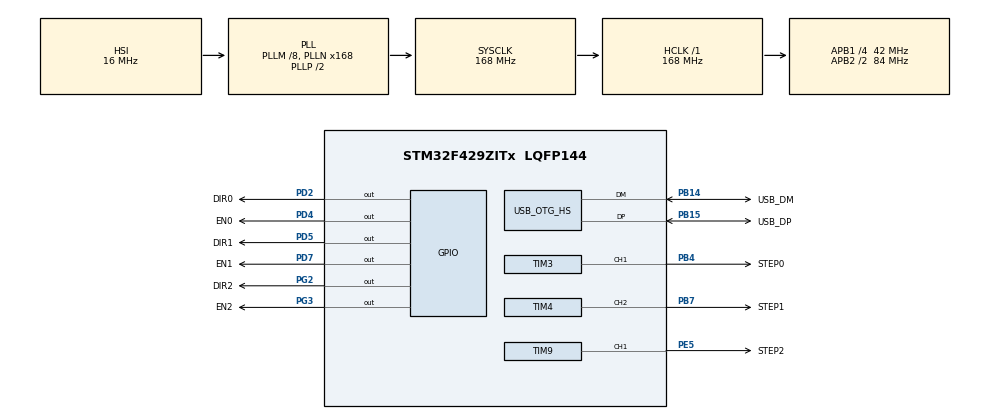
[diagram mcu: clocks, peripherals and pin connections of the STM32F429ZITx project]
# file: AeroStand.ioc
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Mcu.Family=STM32F4
Mcu.Name=STM32F429ZITx
Mcu.Package=LQFP144
NVIC.OTG_HS_IRQn=true\:0\:0\:false\:false\:true\:false\:true\:true
NVIC.TIM1_BRK_TIM9_IRQn=true\:1\:0\:false\:false\:true\:false\:true\:true
NVIC.TIM3_IRQn=true\:1\:0\:false\:false\:true\:false\:true\:true
NVIC.TIM4_IRQn=true\:1\:0\:false\:false\:true\:false\:true\:true
NVIC.PriorityGroup=NVIC_PRIORITYGROUP_4
PA13.GPIO_Label=TMS
PA13.Mode=Serial_Wire
PA13.Signal=SYS_JTMS-SWDIO
PA14.GPIO_Label=TCK
PA14.Mode=Serial_Wire
PA14.Signal=SYS_JTCK-SWCLK
PB14.GPIO_Label=USB_DM
PB14.Mode=Device_Only_FS
PB14.Signal=USB_OTG_HS_DM
PB15.GPIO_Label=USB_DP
PB15.Mode=Device_Only_FS
PB15.Signal=USB_OTG_HS_DP
PB4.GPIO_Label=STEP0
PB4.Signal=S_TIM3_CH1
PB7.GPIO_Label=STEP1
PB7.Signal=S_TIM4_CH2
PD2.GPIO_Label=DIR0
PD2.PinState=GPIO_PIN_RESET
PD2.Signal=GPIO_Output
PD4.GPIO_Label=EN0
PD4.PinState=GPIO_PIN_SET
PD4.Signal=GPIO_Output
PD5.GPIO_Label=DIR1
PD5.PinState=GPIO_PIN_RESET
PD5.Signal=GPIO_Output
PD7.GPIO_Label=EN1
PD7.PinState=GPIO_PIN_SET
PD7.Signal=GPIO_Output
PE5.GPIO_Label=STEP2
PE5.Signal=S_TIM9_CH1
PG2.GPIO_Label=DIR2
PG2.PinState=GPIO_PIN_RESET
PG2.Signal=GPIO_Output
PG3.GPIO_Label=EN2
PG3.PinState=GPIO_PIN_SET
PG3.Signal=GPIO_Output
ProjectManager.HeapSize=0x200
ProjectManager.StackSize=0x400
ProjectManager.TargetToolchain=STM32CubeIDE
RCC.48MHZClocksFreq_Value=48000000
RCC.AHBFreq_Value=168000000
RCC.APB1CLKDivider=RCC_HCLK_DIV4
RCC.APB1Freq_Value=42000000
RCC.APB1TimFreq_Value=84000000
RCC.APB2CLKDivider=RCC_HCLK_DIV2
RCC.APB2Freq_Value=84000000
RCC.APB2TimFreq_Value=168000000
RCC.CortexFreq_Value=168000000
RCC.HCLKFreq_Value=168000000
RCC.HSE_VALUE=8000000
RCC.HSI_VALUE=16000000
RCC.LSE_VALUE=32768
RCC.PLLM=8
RCC.PLLN=168
RCC.PLLSourceVirtual=RCC_PLLSOURCE_HSI
RCC.PLLP=RCC_PLLP_DIV2
RCC.PLLQ=7
RCC.SYSCLKFreq_VALUE=168000000
RCC.SYSCLKSource=RCC_SYSCLKSOURCE_PLLCLK
RCC.VCOOutputFreq_Value=336000000
SH.S_TIM3_CH1.0=TIM3_CH1,PWM Generation1 CH1
SH.S_TIM4_CH2.0=TIM4_CH2,PWM Generation2 CH2
SH.S_TIM9_CH1.0=TIM9_CH1,PWM Generation1 CH1
TIM3.Channel-PWM\ Generation1\ CH1=TIM_CHANNEL_1
TIM4.Channel-PWM\ Generation2\ CH2=TIM_CHANNEL_2
TIM9.Channel-PWM\ Generation1\ CH1=TIM_CHANNEL_1
USB_DEVICE.CLASS_NAME_HS=CDC
USB_DEVICE.VirtualMode-CDC_HS=Cdc
USB_DEVICE.VirtualModeHS=Cdc_HS
USB_OTG_HS.VirtualMode-Device_Only_FS=Device_Only_FS
VP_TIM3_VS_ClockSourceINT.Mode=Internal
VP_TIM4_VS_ClockSourceINT.Mode=Internal
VP_TIM9_VS_ClockSourceINT.Mode=Internal
VP_USB_DEVICE_VS_USB_DEVICE_CDC_HS.Mode=CDC_HS
board=STM32F429I-DISC1

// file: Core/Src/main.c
/* USER CODE BEGIN Header */
/**
  ******************************************************************************
  * @file           : main.c
  * @brief          : Main program body
  ******************************************************************************
  * @attention
  *
  * Copyright (c) 2026 STMicroelectronics.
  * All rights reserved.
  *
  * This software is licensed under terms that can be found in the LICENSE file
  * in the root directory of this software component.
  * If no LICENSE file comes with this software, it is provided AS-IS.
  *
  ******************************************************************************
  */
/* USER CODE END Header */
#include "main.h"
#include "usb_device.h"

/* USER CODE BEGIN Includes */
#include "stepper.h"
#include "cmd_parser.h"
#include "lcd_status.h"
#include "scenario.h"

/* USER CODE END Includes */

TIM_HandleTypeDef htim3;
TIM_HandleTypeDef htim4;
TIM_HandleTypeDef htim9;

void SystemClock_Config(void);
static void MX_GPIO_Init(void);
static void MX_TIM3_Init(void);
static void MX_TIM4_Init(void);
static void MX_TIM9_Init(void);

int main(void)
{

  /* MCU Configuration--------------------------------------------------------*/

  /* Reset of all peripherals, Initializes the Flash interface and the Systick. */
  HAL_Init();

  /* Configure the system clock */
  SystemClock_Config();

  /* Initialize all configured peripherals */
  MX_GPIO_Init();
  MX_TIM3_Init();
  MX_TIM4_Init();
  MX_TIM9_Init();
  MX_USB_DEVICE_Init();
  /* USER CODE BEGIN 2 */
  stepper_init();
  cmd_init();
  (void)lcd_status_init();

  /* USER CODE END 2 */

  /* Infinite loop */
  while (1)
  {

    /* USER CODE BEGIN 3 */
    cmd_poll();
    scenario_update();
    lcd_status_update();
  }
  /* USER CODE END 3 */
}

void SystemClock_Config(void)
{
  RCC_OscInitTypeDef RCC_OscInitStruct = {0};
  RCC_ClkInitTypeDef RCC_ClkInitStruct = {0};

  /** Configure the main internal regulator output voltage
  */
  __HAL_RCC_PWR_CLK_ENABLE();
  __HAL_PWR_VOLTAGESCALING_CONFIG(PWR_REGULATOR_VOLTAGE_SCALE1);

  /** HSI 16 МГц -> PLL: VCO 16/8 = 2 МГц x 168 = 336, SYSCLK 168, USB 48 (HSE на плате не стартует) */
  RCC_OscInitStruct.OscillatorType = RCC_OSCILLATORTYPE_HSI;
  RCC_OscInitStruct.HSIState = RCC_HSI_ON;
  RCC_OscInitStruct.HSICalibrationValue = RCC_HSICALIBRATION_DEFAULT;
  RCC_OscInitStruct.PLL.PLLState = RCC_PLL_ON;
  RCC_OscInitStruct.PLL.PLLSource = RCC_PLLSOURCE_HSI;
  RCC_OscInitStruct.PLL.PLLM = 8;
  RCC_OscInitStruct.PLL.PLLN = 168;
  RCC_OscInitStruct.PLL.PLLP = RCC_PLLP_DIV2;
  RCC_OscInitStruct.PLL.PLLQ = 7;
  if (HAL_RCC_OscConfig(&RCC_OscInitStruct) != HAL_OK)
  {
    Error_Handler();
  }

  /** Initializes the CPU, AHB and APB buses clocks
  */
  RCC_ClkInitStruct.ClockType = RCC_CLOCKTYPE_HCLK|RCC_CLOCKTYPE_SYSCLK
                              |RCC_CLOCKTYPE_PCLK1|RCC_CLOCKTYPE_PCLK2;
  RCC_ClkInitStruct.SYSCLKSource = RCC_SYSCLKSOURCE_PLLCLK;
  RCC_ClkInitStruct.AHBCLKDivider = RCC_SYSCLK_DIV1;
  RCC_ClkInitStruct.APB1CLKDivider = RCC_HCLK_DIV4;
  RCC_ClkInitStruct.APB2CLKDivider = RCC_HCLK_DIV2;

  if (HAL_RCC_ClockConfig(&RCC_ClkInitStruct, FLASH_LATENCY_5) != HAL_OK)
  {
    Error_Handler();
  }
}

static void MX_TIM3_Init(void)
{

  TIM_ClockConfigTypeDef sClockSourceConfig = {0};
  TIM_MasterConfigTypeDef sMasterConfig = {0};
  TIM_OC_InitTypeDef sConfigOC = {0};

  htim3.Instance = TIM3;
  htim3.Init.Prescaler = 0;
  htim3.Init.CounterMode = TIM_COUNTERMODE_UP;
  htim3.Init.Period = 65535;
  htim3.Init.ClockDivision = TIM_CLOCKDIVISION_DIV1;
  htim3.Init.AutoReloadPreload = TIM_AUTORELOAD_PRELOAD_DISABLE;
  if (HAL_TIM_Base_Init(&htim3) != HAL_OK)
  {
    Error_Handler();
  }
  sClockSourceConfig.ClockSource = TIM_CLOCKSOURCE_INTERNAL;
  if (HAL_TIM_ConfigClockSource(&htim3, &sClockSourceConfig) != HAL_OK)
  {
    Error_Handler();
  }
  if (HAL_TIM_PWM_Init(&htim3) != HAL_OK)
  {
    Error_Handler();
  }
  sMasterConfig.MasterOutputTrigger = TIM_TRGO_RESET;
  sMasterConfig.MasterSlaveMode = TIM_MASTERSLAVEMODE_DISABLE;
  if (HAL_TIMEx_MasterConfigSynchronization(&htim3, &sMasterConfig) != HAL_OK)
  {
    Error_Handler();
  }
  sConfigOC.OCMode = TIM_OCMODE_PWM1;
  sConfigOC.Pulse = 0;
  sConfigOC.OCPolarity = TIM_OCPOLARITY_HIGH;
  sConfigOC.OCFastMode = TIM_OCFAST_DISABLE;
  if (HAL_TIM_PWM_ConfigChannel(&htim3, &sConfigOC, TIM_CHANNEL_1) != HAL_OK)
  {
    Error_Handler();
  }
  HAL_TIM_MspPostInit(&htim3);

}

static void MX_TIM4_Init(void)
{

  TIM_ClockConfigTypeDef sClockSourceConfig = {0};
  TIM_MasterConfigTypeDef sMasterConfig = {0};
  TIM_OC_InitTypeDef sConfigOC = {0};

  htim4.Instance = TIM4;
  htim4.Init.Prescaler = 0;
  htim4.Init.CounterMode = TIM_COUNTERMODE_UP;
  htim4.Init.Period = 65535;
  htim4.Init.ClockDivision = TIM_CLOCKDIVISION_DIV1;
  htim4.Init.AutoReloadPreload = TIM_AUTORELOAD_PRELOAD_DISABLE;
  if (HAL_TIM_Base_Init(&htim4) != HAL_OK)
  {
    Error_Handler();
  }
  sClockSourceConfig.ClockSource = TIM_CLOCKSOURCE_INTERNAL;
  if (HAL_TIM_ConfigClockSource(&htim4, &sClockSourceConfig) != HAL_OK)
  {
    Error_Handler();
  }
  if (HAL_TIM_PWM_Init(&htim4) != HAL_OK)
  {
    Error_Handler();
  }
  sMasterConfig.MasterOutputTrigger = TIM_TRGO_RESET;
  sMasterConfig.MasterSlaveMode = TIM_MASTERSLAVEMODE_DISABLE;
  if (HAL_TIMEx_MasterConfigSynchronization(&htim4, &sMasterConfig) != HAL_OK)
  {
    Error_Handler();
  }
  sConfigOC.OCMode = TIM_OCMODE_PWM1;
  sConfigOC.Pulse = 0;
  sConfigOC.OCPolarity = TIM_OCPOLARITY_HIGH;
  sConfigOC.OCFastMode = TIM_OCFAST_DISABLE;
  if (HAL_TIM_PWM_ConfigChannel(&htim4, &sConfigOC, TIM_CHANNEL_2) != HAL_OK)
  {
    Error_Handler();
  }
  HAL_TIM_MspPostInit(&htim4);

}

static void MX_TIM9_Init(void)
{

  TIM_ClockConfigTypeDef sClockSourceConfig = {0};
  TIM_OC_InitTypeDef sConfigOC = {0};

  htim9.Instance = TIM9;
  htim9.Init.Prescaler = 0;
  htim9.Init.CounterMode = TIM_COUNTERMODE_UP;
  htim9.Init.Period = 65535;
  htim9.Init.ClockDivision = TIM_CLOCKDIVISION_DIV1;
  htim9.Init.AutoReloadPreload = TIM_AUTORELOAD_PRELOAD_DISABLE;
  if (HAL_TIM_Base_Init(&htim9) != HAL_OK)
  {
    Error_Handler();
  }
  sClockSourceConfig.ClockSource = TIM_CLOCKSOURCE_INTERNAL;
  if (HAL_TIM_ConfigClockSource(&htim9, &sClockSourceConfig) != HAL_OK)
  {
    Error_Handler();
  }
  if (HAL_TIM_PWM_Init(&htim9) != HAL_OK)
  {
    Error_Handler();
  }
  sConfigOC.OCMode = TIM_OCMODE_PWM1;
  sConfigOC.Pulse = 0;
  sConfigOC.OCPolarity = TIM_OCPOLARITY_HIGH;
  sConfigOC.OCFastMode = TIM_OCFAST_DISABLE;
  if (HAL_TIM_PWM_ConfigChannel(&htim9, &sConfigOC, TIM_CHANNEL_1) != HAL_OK)
  {
    Error_Handler();
  }
  HAL_TIM_MspPostInit(&htim9);

}

static void MX_GPIO_Init(void)
{
  GPIO_InitTypeDef GPIO_InitStruct = {0};

  /* GPIO Ports Clock Enable */
  __HAL_RCC_GPIOE_CLK_ENABLE();
  __HAL_RCC_GPIOH_CLK_ENABLE();
  __HAL_RCC_GPIOB_CLK_ENABLE();
  __HAL_RCC_GPIOG_CLK_ENABLE();
  __HAL_RCC_GPIOA_CLK_ENABLE();
  __HAL_RCC_GPIOD_CLK_ENABLE();

  /*Configure GPIO pin Output Level */
  HAL_GPIO_WritePin(DIR2_GPIO_Port, DIR2_Pin, GPIO_PIN_RESET);

  /*Configure GPIO pin Output Level */
  HAL_GPIO_WritePin(EN2_GPIO_Port, EN2_Pin, GPIO_PIN_SET);

  /*Configure GPIO pin Output Level */
  HAL_GPIO_WritePin(GPIOD, DIR0_Pin|DIR1_Pin, GPIO_PIN_RESET);

  /*Configure GPIO pin Output Level */
  HAL_GPIO_WritePin(GPIOD, EN0_Pin|EN1_Pin, GPIO_PIN_SET);

  /*Configure GPIO pins : DIR2_Pin EN2_Pin */
  GPIO_InitStruct.Pin = DIR2_Pin|EN2_Pin;
  GPIO_InitStruct.Mode = GPIO_MODE_OUTPUT_PP;
  GPIO_InitStruct.Pull = GPIO_NOPULL;
  GPIO_InitStruct.Speed = GPIO_SPEED_FREQ_LOW;
  HAL_GPIO_Init(GPIOG, &GPIO_InitStruct);

  /*Configure GPIO pins : DIR0_Pin EN0_Pin DIR1_Pin EN1_Pin */
  GPIO_InitStruct.Pin = DIR0_Pin|EN0_Pin|DIR1_Pin|EN1_Pin;
  GPIO_InitStruct.Mode = GPIO_MODE_OUTPUT_PP;
  GPIO_InitStruct.Pull = GPIO_NOPULL;
  GPIO_InitStruct.Speed = GPIO_SPEED_FREQ_LOW;
  HAL_GPIO_Init(GPIOD, &GPIO_InitStruct);

}

void Error_Handler(void)
{
  __disable_irq();
  while (1)
  {
  }
}
